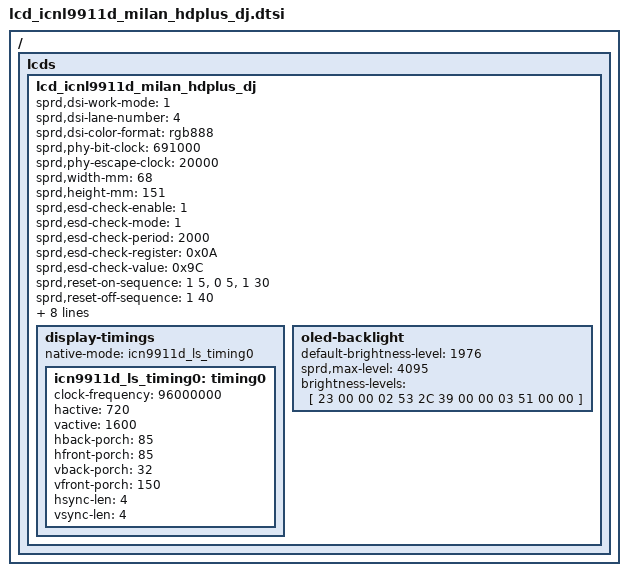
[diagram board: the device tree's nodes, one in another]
/ {
	fragment {
		target-path = "/";
		__overlay__ {
			lcds {
				lcd_icnl9911d_milan_hdplus_dj: lcd_icnl9911d_milan_hdplus_dj {

					sprd,dsi-work-mode = <1>;
					sprd,dsi-lane-number = <4>;
					sprd,dsi-color-format = "rgb888";

					sprd,phy-bit-clock = <691000>;	/* kbps */
					sprd,phy-escape-clock = <20000>;

					sprd,width-mm = <68>;
					sprd,height-mm = <151>;

					sprd,esd-check-enable = <1>;
					sprd,esd-check-mode = <1>;  /*Read register*/
					sprd,esd-check-period = <2000>;
					sprd,esd-check-register = <0x0A>;
					sprd,esd-check-value = <0x9C>;

					sprd,reset-on-sequence = <1 5>, <0 5>, <1 30>;
					sprd,reset-off-sequence = <1 40>;

					sprd,initial-command = [
			39 00 00 04 F0 99 11 0D
			39 00 00 1F B2 87 86 05 04 8A 8B 04 05 55 55 55 55 0A 00 00 64 00 00 0F 05 04 03 02 01 02 03 04 00 00 00
			39 00 00 1E B3 53 42 85 00 0A 00 00 64 00 00 04 08 54 00 00 00 44 40 02 01 40 02 01 40 02 01 40 02 01
			39 00 00 12 B4 54 84 85 05 40 02 01 40 02 01 05 05 54 0C 0C 0D 0B
			39 00 00 20 B5 02 0E 0B 0E 0B 26 26 91 A2 33 44 00 26 00 18 01 02 08 20 30 08 09 44 20 40 20 40 08 09 22 33
			39 00 00 1D B6 02 02 00 00 E3 09 22 00 22 0D 0F 11 13 05 02 02 02 02 02 02 02 02 FF FF FC 00 00 00
			39 00 00 1D B7 00 00 00 00 E3 08 22 00 22 0C 0E 10 12 04 02 02 02 02 02 02 02 02 FF FF FC 00 00 00
			39 00 00 19 BA 00 00 00 00 00 00 00 00 00 00 00 00 AA AA AA AA AA A0 AA AA AA AA AA A0
			39 00 00 0E BB 01 05 09 11 0D 19 1D 55 25 69 00 21 25
			39 00 00 10 BC 00 00 00 00 02 20 FF 00 07 33 01 73 33 02 01
			39 00 00 0B BD E9 83 5F CF 72 A6 06 1B AE 15
			39 00 00 0C BE 82 82 4D 51 07 BB 43 08 0E 0E 6B
			39 00 00 09 BF 07 25 07 25 7F 00 11 04
			39 00 00 12 C1 C0 00 20 20 96 04 55 55 04 2A 40 36 00 07 CF FF FF
			23 00 00 02 C2 00
			39 00 00 0B C3 06 00 FF 00 FF 40 4D 01 00 02
			39 00 00 0C C5 03 1C C0 C0 40 10 42 44 0F 0F 14
			39 00 00 0B C6 87 96 2A 29 29 33 7F 34 0F 04
			39 00 00 21 C7 13 33 33 33 33 33 33 33 30 63 33 33 33 33 33 33 33 30 31 00 FF FF 01 00 00 0C 00 00 00 00 00 00
			39 00 00 21 83 FF FB F4 EE E8 E3 DF DB D5 C8 BD B4 AA A3 9D 92 88 7F 77 76 6E 66 5D 53 47 38 2F 23 20 1C 17 12
			39 00 00 21 84 FF FB F4 EE E8 E3 DF DB D5 C8 BD B4 AA A3 9D 92 88 7F 77 76 6E 66 5D 53 47 38 2F 23 20 1C 17 12
			39 00 00 21 85 FF FB F4 EE E8 E3 DF DB D5 C8 BD B4 AA A3 9D 92 88 7F 77 76 6E 66 5D 53 47 38 2F 23 20 1C 17 12
			39 00 00 1A 86 03 0C 06 00 00 0C 06 00 00 0C 06 00 00 0A 06 02 00 0A 06 02 00 0A 06 02 00
			39 00 00 1C 87 FF 33 E8 F4 51 46 B7 09 C8 FF 33 E8 F4 51 46 B7 09 C8 FF 33 E8 F4 51 46 B7 09 C8
			39 00 00 09 D0 80 0D FF 0F 62 0B 08 04
			39 00 00 09 E0 0C 00 B8 10 00 00 10 06
			39 00 00 04 F0 A5 A5 A5
			23 00 00 02 53 2C
			23 00 00 02 55 00
			23 00 00 02 35 00
			23 78 00 02 11 00
			23 23 00 02 29 00
			23 05 00 02 26 01
						];
			sprd,page-unlock-command = [
			39 00 00 04 F0 99 11 0D
						];
					sprd,sleep-in-command = [
			23 00 00 02 26 08
			23 23 00 02 28 00
			23 78 00 02 10 00
						];
					sprd,sleep-out-command = [
			23 78 00 02 11 00
			23 23 00 02 29 00
			23 00 00 02 26 01
						];

					display-timings {
						native-mode = <&icn9911d_ls_timing0>;

						icn9911d_ls_timing0: timing0 {
							clock-frequency = <96000000>;
				hactive = <720>;
				vactive = <1600>;
				hback-porch = <85>;
				hfront-porch = <85>;
				vback-porch = <32>;
				vfront-porch = <150>;
				hsync-len = <4>;
				vsync-len = <4>;
						};
					};
				oled-backlight {
						default-brightness-level = <1976>;
						sprd,max-level = <4095>;
						brightness-levels = [
							23 00 00 02 53 2C
            		    	39 00 00 03 51 00 00
						];
					};

				};
			};
		};
	};
};

